# DPLL_VIDEO1_L4_CFG register map
Vendor: Texas Instruments
Peripheral module from a debugger description file (folder DRA75x_DRA74x).
Registers are 32-bit, access per field, reset 0x0 unless marked. A register's access mark holds for its fields unless they carry their own. Offsets are as the file gives them; lines under a group give offsets from that group; [hi:lo] are bit positions; {n}, {i} and the like mark numbered series; 'fields as' and 'values as' point back to an identical list; <NAME> marks a mode.

## DPLL_VIDEO1_L4_CFG
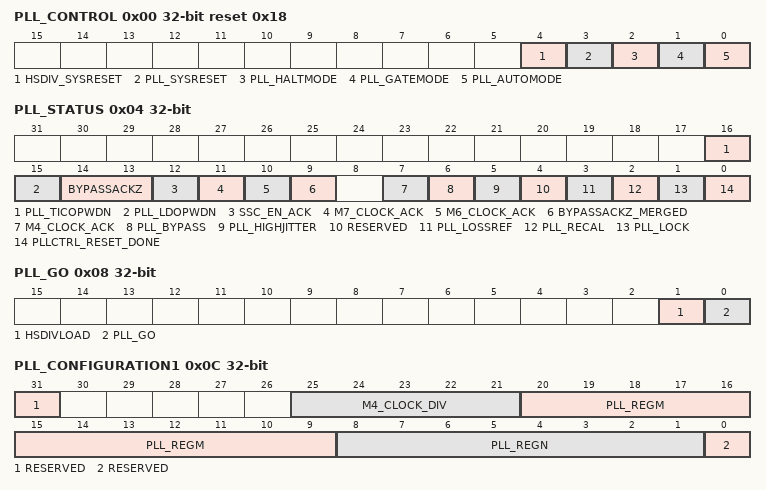
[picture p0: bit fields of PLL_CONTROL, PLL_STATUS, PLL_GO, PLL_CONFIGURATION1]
0x00 PLL_CONTROL reset 0x18 — This register controls the PLL reset/power and modes
  [4] HSDIV_SYSRESET rw — Force HSDIVIDER SYSRESETN. Reserved when DBGSSV is 1.
    0=HSDIVIDER_SYSRESET_forced_active; 1=HSDIVIDER_SYSRESET_FSM_1 (HSDIVIDER SYSRESET controlled by power FSM)
  [3] PLL_SYSRESET rw — Force DPLL SYSRESETN. Reserved when DBGSSV is 1.
    0=PLL_SYSRESET_forced_active; 1=PLL_SYSRESET_controlled_by_power_FSM
  [2] PLL_HALTMODE rw — Allow PLL to be halted if no activity. Reserved when PLLCTRL_AUTO is 0.
    0=PLL_will_not_be_halted; 1=PLL_will_be_halted_based_on_activity
  [1] PLL_GATEMODE rw — Allow PLL clock gating for power saving Reserved when PLLCTRL_AUTO is 0.
    0=PHY_clock_on
  [0] PLL_AUTOMODE rw — Automatic update mode. If this bit is set then the configuration updates will be synchronized to DISPCUpdateSync. If this bit is clear configuration updates will be done immediately. Reserved when PLLCTRL_AUTO is 0.
    0=Manual_mode; 1=Automatic_mode
0x04 PLL_STATUS ro — This register contains the status information
  [16] PLL_TICOPWDN — PLL TICOPWDN status.
    1=Ticopwdn_high (Internal oscillator power down); 0=Ticopwdn_low (Internal oscillator power up)
  [15] PLL_LDOPWDN — PLL LDOPWDN status.
    1=Ldopwdn_high (PLL's internal LDO is power down); 0=Ldopwdn_low (PLL's internal LDO is power up)
  [14:13] BYPASSACKZ — State of bypass mode on PHY and HSDIVIDER. The status is shown separately for each source.
    1=Bypass_Nak (PLL outputs are still being used by the PHY or HSDIVIDER.); 0=Bypass_Ack (PHY or HSDIVIDER has switched to using the bypass clocks.)
  [12] SSC_EN_ACK — Spread Spectrum Clocking acknowledgeNote: SSC feature is not supported. enum=SSC_inact .
    1=SSC_act (Spread Spectrum Clocking active); 0=SSC_act (Spread Spectrum Clocking inactive)
  [11] M7_CLOCK_ACK — Acknowledge for enable of sub-system clock Verify the status before selecting this source in the sub-system clock mux
    0=M7_clock_inactive; 1=M7_clock_active
  [10] M6_CLOCK_ACK — Acknowledge for enable of sub-system clock Verify the status before selecting this source in the sub-system clock mux
    1=M6_Clk_Act (M6 clock active); 0=M6_Clk_Inact (M6 clock inactive)
  [9] BYPASSACKZ_MERGED — Merged state of bypass mode on PHY and HSDIVIDER
    1=Bypass_Nak (PLL outputs are still being used by the PHY or HSDIVIDER); 0=Bypass_Ack (PHY and HSDIVIDER have switched to using the bypass clocks.)
  [7] M4_CLOCK_ACK — Acknowledge for enable of sub-system clock Verify the status before selecting this source in the sub-system clock mux
    1=M4_Clk_Act (M4 clock active); 0=M4_Clk_Inact (M4 clock inactive)
  [6] PLL_BYPASS — PLL Bypass status
    1=Bypass_Act (PLL bypass); 0=Bypass_In (PLL not bypassing)
  [5] PLL_HIGHJITTER — PLL High Jitter status
    1=High_Jiitter (PLL in high jitter condition: Phase error > 24%); 0=Normal_Jitter (PLL in normal jitter condition)
  [4] RESERVED — Read returns zero.
  [3] PLL_LOSSREF — PLL Reference Loss status
    1=Ref_Inp_Inact (Reference input inactive); 0=Ref_Inp_Act (Reference input active)
  [2] PLL_RECAL — PLL re-calibration status If this bit is active, the PLL needs to be re-calibrated
    1=Recal_required (Recalibration is required); 0=Recal_not_required (Recalibration is not required)
  [1] PLL_LOCK — PLL Lock status See the programming guide for the use of this bit
    1=DSI_PLL_Lock (PLL is locked); 0=DSI_PLL_NoLock (PLL is not locked)
  [0] PLLCTRL_RESET_DONE — PLLCTRL reset done status
    1=RDone (Reset has completed); 0=NotRD (Reset is in progress)
0x08 PLL_GO — This register contains the GO bit
  [1] HSDIVLOAD rw — In manual mode start HSDIVIDER update sequence.
  [0] PLL_GO rw — Request (re-)locking sequence of the PLL. If the AutoMode bit is set, then this will be deferred until DISPCUpdate Sync goes active
    0=No_pending_action; 1=PLL_1 (Request PLL (re-)locking/locking pending)
0x0C PLL_CONFIGURATION1 — This register contains the latched PLL and HSDIVDER configuration bits
  [31] RESERVED ro — Read returns zero.
  [25:21] M4_CLOCK_DIV rw — Divider value for clock source M4REG Divider value = M4_CLOCK_DIV + 1
  [20:9] PLL_REGM rw — M Divider for PLL. Valid values range is from 1 to 2047. Values 2048 and above are reserved and must not be used. When the PLL_REGM bit field is set to 1, the PLL enters a MN-Bypass mode. The DCOCLK clock output goes low and remains low until the PLL exits MN-Bypass mode (by changing the PLL_REGM bit field to a value other than 0 or 1).
  [8:1] PLL_REGN rw — N Divider for PLL (Reference). Divider value = PLL_REGN+1. Valid values range is from 0 to 127. Values 128 and above are reserved and must not be used.
  [0] RESERVED ro — Read returns zero.
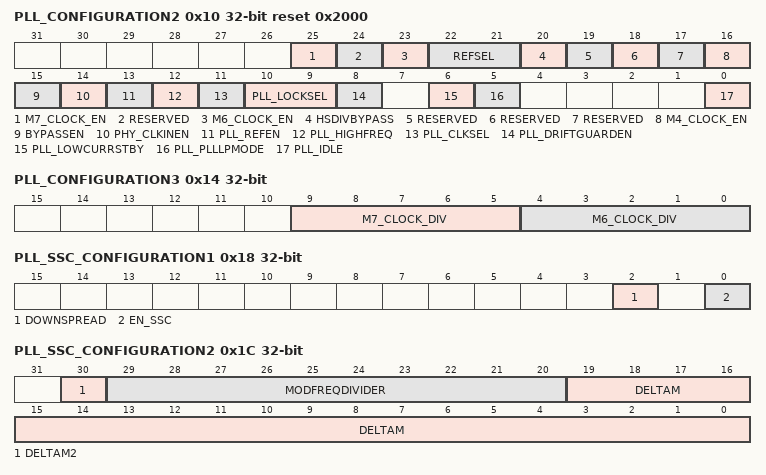
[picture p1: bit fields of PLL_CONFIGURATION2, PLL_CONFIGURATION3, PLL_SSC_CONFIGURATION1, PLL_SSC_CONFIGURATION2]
0x10 PLL_CONFIGURATION2 reset 0x2000 — This register contains the unlatched PLL and HSDIVDER configuration bits These bits are 'shadowed' when automatic mode is selected
  [25] M7_CLOCK_EN rw — Enable for M7 clock source
    0=M7_clock_divider_is_disabled; 1=M7_clock_divider_is_enabled
  [24] RESERVED ro — Read returns zero.
  [23] M6_CLOCK_EN rw — Enable for M6 clock source
    0=M6_Clk_Dis (M6 clock divider is disabled); 1=M6_Clk_En (M6 clock divider is enabled)
  [22:21] REFSEL rw — Selects the reference clock with optional divide by 2
    0=Ref_PCLK (Reserved); 1=Ref_1 (Reserved); 3=Ref_SYSCLK (Select SYSCLK reference); 2=Ref_2 (Reserved)
  [20] HSDIVBYPASS rw — Forces HSDIVIDER to bypass mode
    0=HSDIV_Normal (HSDIVIDER in normal operation. Bypass controlled by PLL.); 1=HSDIV_Force_Byp (HSDIVIDER forced to bypass mode.)
  [19] RESERVED ro — Read returns zero.
  [18] RESERVED ro — Read returns zero.
  [17] RESERVED ro — Read returns zero
  [16] M4_CLOCK_EN rw — Enable for M4 clock source
    0=SS_Clk_Dis (Sub-system clock divider is disabled); 1=SS_Clk_En (Sub-system clock divider is enabled)
  [15] BYPASSEN rw — Selects sub-system functional clock as PHY clock source
    0=Clk_PLL (PLL controls the PHY clock source: PLL DCO if PLL is locked Sub-system functional clock if not locked); 1=Clk_Bypass (Force sub-system functional clock to be used as the PHY clock source)
  [14] PHY_CLKINEN rw — PHY clock control
    0=PHY_Clk_Dis (PHY clock is disabled); 1=PHY_Clk_En (PHY clock is enabled)
  [13] PLL_REFEN rw — PLL reference clock control
    0=Ref_dis (PLL reference clock disabled); 1=Ref_en (PLL reference clock enabled)
  [12] PLL_HIGHFREQ rw — Enables a division of pixel clock by 2 before input to the PLL Required for pixel clock frequencies above 32 MHz (21 MHZ if N = 0)
    0=DIV_BY_1 (Pixel clock is not divided); 1=DIV_BY_2 (Pixel clock is divided by 2)
  [11] PLL_CLKSEL rw — Reference clock selection
    0=SYSCLK_Ref (Selects SYSCLK as PLL reference clock); 1=PCLK_Ref (Selects Pixel Clock (PCLK) as PLL reference clock)
  [10:9] PLL_LOCKSEL rw — Selects the lock criteria for the PLL
    0=PHASELOCK; 1=FREQLOCK (Frequency Lock); 2=SPARE
  [8] PLL_DRIFTGUARDEN rw
    0=Drift_Guard_Dis (Only RECAL flag is asserted in case of temperature drift. The programmer should take appropriate action.); 1=Drift_Guard_En (Temperature drift will initiate automatic recalibration. RECAL flag will be asserted while this is taking place.)
  [6] PLL_LOWCURRSTBY rw — PLL LOW CURRENT STANDBY
    0=LOWCURRSTBY_notsel (LOWCURRSTBY is not selected); 1=LOWCURRSTBY_sel (LOWCURRSTBY is selected)
  [5] PLL_PLLLPMODE rw — Select the power / performance of the PLL
    0=FULL_PERF (Full performance, minimized jitter); 1=REDUCE_PERF (Reduced power, increased jitter)
  [0] PLL_IDLE rw
    0=IDLE_notsel (IDLE is not selected); 1=IDLE_sel (IDLE is selected)
0x14 PLL_CONFIGURATION3 — HSDIVIDER configuration bits for the M5 and M6 dividers
  [9:5] M7_CLOCK_DIV rw — Divider value for M7 divider. Divider value = M7_CLOCK_DIV + 1
  [4:0] M6_CLOCK_DIV rw — Divider value for M6 divider. Divider value = M6_CLOCK_DIV + 1
0x18 PLL_SSC_CONFIGURATION1 — Configuration for PLL Spread Spectrum Clocking modulation. Note: SSC feature is not supported.
  [2] DOWNSPREAD rw — Forces the clock spreading only in the down spectrum.
    0=Clock_spreading_not_forced; 1=Spectrum spreading only in down direction
  [0] EN_SSC rw — Spread Spectrum Clocking enable 0x0: Spread Spectrum Clocking disabled 0x1: Spread Spectrum Clocking enabled
0x1C PLL_SSC_CONFIGURATION2 — Configuration for PLL Spread Spectrum Clocking modulation. Note: SSC feature is not supported.
  [30] DELTAM2 rw — MSB of DeltaM control bus.
  [29:20] MODFREQDIVIDER rw — Modulation Frequency Divider (ModFreqDivider) control for SSC. The ModFreqDivider is split into Mantissa and 2^Exponent(ModFreqDivider = ModFreqDividerMantissa * 2^ModFreqDividerExponent). - Bits [29:23] define the Mantissa. - Bits [22:20] define the Exponent.
  [19:0] DELTAM rw — DeltaM control for SSC. Split into integer and fractional parts. - Bits [19:18] define the integer part. - Bits [17:0] define the fractional part.
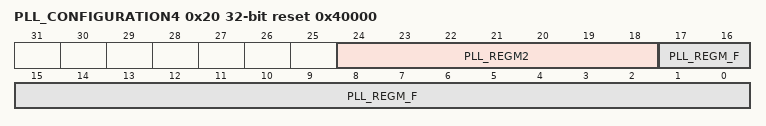
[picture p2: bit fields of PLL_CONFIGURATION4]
0x20 PLL_CONFIGURATION4 reset 0x40000 — Allows setting the fractional M divider and M2 divider for PLL.
  [24:18] PLL_REGM2 rw — M2 divider to configure PLL REGM2. NOTE: In this device, M2 divider is hardcoded in HW at 31 (0x1F).
  [17:0] PLL_REGM_F rw — Fractional part of M divider. NOTE: The feature is not supported in this device.
